# D1H register map
Vendor: Allwinner; File version: 1.0
Registers are 32-bit, read-write, reset 0x0 unless marked. A register's access mark holds for its fields unless they carry their own. Offsets are from the block's base; [hi:lo] are bit positions; {n}, {i} and the like mark numbered series.

## EMAC — Ethernet Medium Access Controller
Base 0x04500000
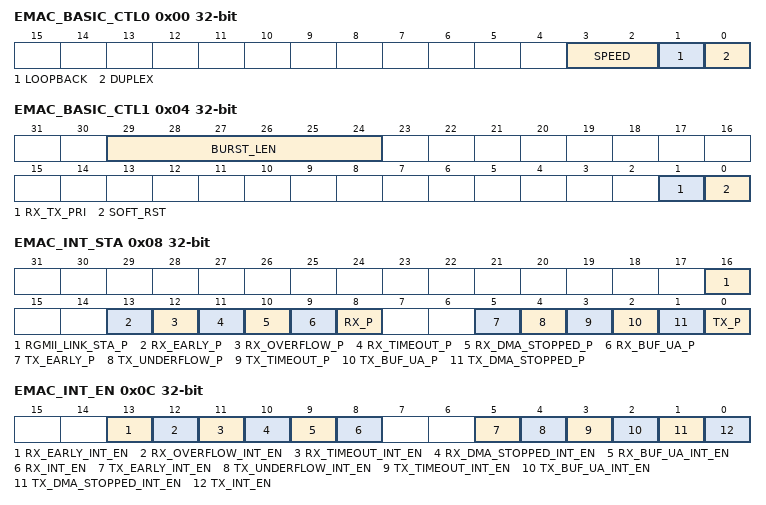
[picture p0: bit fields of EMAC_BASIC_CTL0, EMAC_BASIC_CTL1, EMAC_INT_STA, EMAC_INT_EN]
0x00 EMAC_BASIC_CTL0 — EMAC Basic Control Register0
  [3:2] SPEED — EMAC Working Speed
    0=S1000; 2=S10; 3=S100
  [1] LOOPBACK — EMAC Loopback Mode For Test
    0=Disable; 1=Enable
  [0] DUPLEX — EMAC Transfer Mode
    0=Half_Duplex; 1=Full_Duplex
0x04 EMAC_BASIC_CTL1 — EMAC Basic Control Register1
  [29:24] BURST_LEN — The burst length of RX and TX DMA transfer
  [1] RX_TX_PRI — RX TX DMA Priority
    0=Same; 1=RoT
  [0] SOFT_RST — Soft Reset all Registers and Logic
    0=no_valid; 1=reset
0x08 EMAC_INT_STA write-1-clears — EMAC Interrupt Status Register
  [16] RGMII_LINK_STA_P — RMII Link Status Changed Interrupt Pending
    0=No_Pending; 1=Pending
  [13] RX_EARLY_P — RX DMA Filled First Data Buffer of the Receive Frame Interrupt Pending
    0=no_pending; 1=pending
  [12] RX_OVERFLOW_P — RX FIFO Overflow Error Interrupt Pending
    0=no_pending; 1=pending
  [11] RX_TIMEOUT_P — RX Timeout Interrupt Pending
    0=no_pending; 1=pending
  [10] RX_DMA_STOPPED_P — When this bit asserted, the RX DMA FSM is stopped.
  [9] RX_BUF_UA_P — RX Buffer UA Interrupt Pending
    0=no_pending; 1=pending
  [8] RX_P — Frame RX Completed Interrupt Pending
    0=no_pending; 1=pending
  [5] TX_EARLY_P — Total interrupt pending which the frame is transmitted to FIFO
    0=no_pending; 1=pending
  [4] TX_UNDERFLOW_P — TX FIFO Underflow Interrupt Pending
    0=no_pending; 1=pending
  [3] TX_TIMEOUT_P — Transmitter Timeout Interrupt Pending
    0=no_pending; 1=pending
  [2] TX_BUF_UA_P — TX Buffer UA Interrupt Pending
    0=no_pending; 1=pending
  [1] TX_DMA_STOPPED_P — Transmission DMA Stopped Interrupt Pending
    0=no_pending; 1=pending
  [0] TX_P — Frame Transmission Interrupt Pending
    0=no_pending; 1=pending
0x0C EMAC_INT_EN — EMAC Interrupt Enable Register
  [all] fields
    0=Disable; 1=Enable
  [13] RX_EARLY_INT_EN — Early Receive Interrupt
  [12] RX_OVERFLOW_INT_EN — Receive Overflow Interrupt
  [11] RX_TIMEOUT_INT_EN — Receive Timeout Interrupt
  [10] RX_DMA_STOPPED_INT_EN — Receive DMA FSM Stopped Interrupt
  [9] RX_BUF_UA_INT_EN — Receive Buffer Unavailable Interrupt
  [8] RX_INT_EN — Receive Interrupt
  [5] TX_EARLY_INT_EN — Early Transmit Interrupt
  [4] TX_UNDERFLOW_INT_EN — Transmit Underflow Interrupt
  [3] TX_TIMEOUT_INT_EN — Transmit Timeout Interrupt
  [2] TX_BUF_UA_INT_EN — Transmit Buffer Available Interrupt
  [1] TX_DMA_STOPPED_INT_EN — Transmit DMA FSM Stopped Interrupt
  [0] TX_INT_EN — Transmit Interrupt
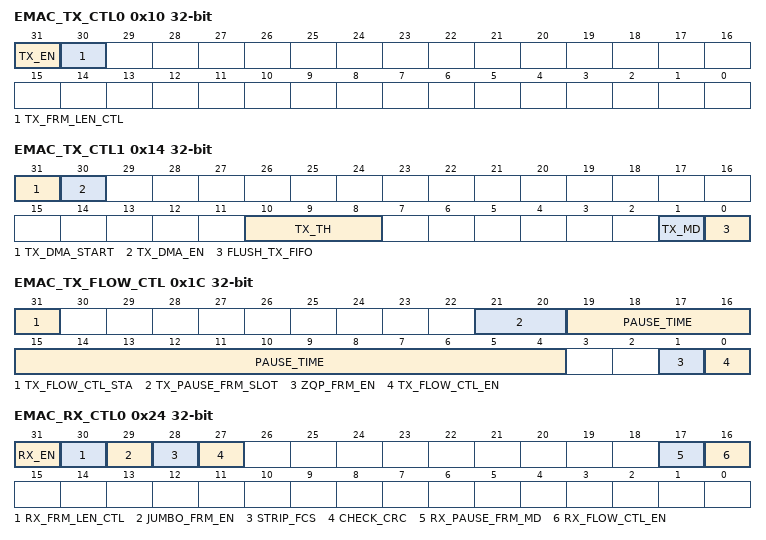
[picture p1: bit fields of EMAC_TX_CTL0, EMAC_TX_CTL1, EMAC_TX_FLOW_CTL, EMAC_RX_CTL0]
0x10 EMAC_TX_CTL0 — EMAC Transmit Control Register0
  [31] TX_EN — Enable Transmitter
    0=Disable; 1=Enable
  [30] TX_FRM_LEN_CTL — Frame Transmit Length Control
    0=B2048; 1=B16384
0x14 EMAC_TX_CTL1 — EMAC Transmit Control Register1
  [31] TX_DMA_START — Transmit DMA FSM Start
    0=no_valid; 1=start
  [30] TX_DMA_EN — Transmit DMA Enable
    0=stop; 1=start
  [10:8] TX_TH — Threshold value of TX DMA FIFO
    0=T64; 1=T128; 2=T192; 3=T256
  [1] TX_MD — Transmission Mode
    0=greater_than_th; 1=locate_full_frame
  [0] FLUSH_TX_FIFO — Flush the data in the TX FIFO
    0=enable; 1=disable
0x1C EMAC_TX_FLOW_CTL — EMAC Transmit Flow Control Register
  [31] TX_FLOW_CTL_STA
  [21:20] TX_PAUSE_FRM_SLOT
  [19:4] PAUSE_TIME
  [1] ZQP_FRM_EN
    0=disable; 1=enable
  [0] TX_FLOW_CTL_EN — TX Flow Control Enable
    0=disable; 1=enable
0x20 EMAC_TX_DMA_DESC_LIST — EMAC Transmit Descriptor List Address Register
0x24 EMAC_RX_CTL0 — EMAC Receive Control Register0
  [31] RX_EN — Enable Receiver
    0=disable; 1=enable
  [30] RX_FRM_LEN_CTL — Frame Receive Length Control
    0=B2048; 1=B16384
  [29] JUMBO_FRM_EN — Jumbo Frame Enable
    0=disable; 1=enable
  [28] STRIP_FCS
  [27] CHECK_CRC — Check CRC Enable
    0=disable; 1=check
  [17] RX_PAUSE_FRM_MD
    0=only_multicast; 1=also_unicast_mac0
  [16] RX_FLOW_CTL_EN
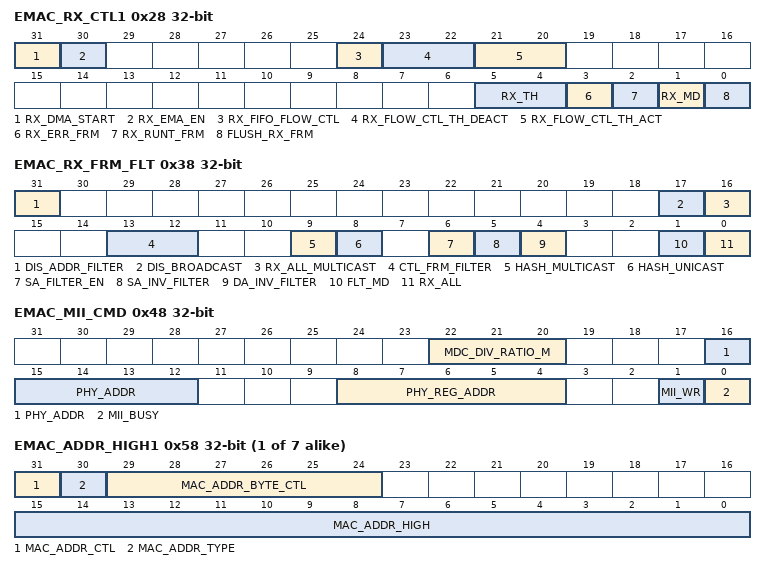
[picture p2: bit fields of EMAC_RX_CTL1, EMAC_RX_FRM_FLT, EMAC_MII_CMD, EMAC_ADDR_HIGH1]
0x28 EMAC_RX_CTL1 — EMAC Receive Control Register1
  [31] RX_DMA_START
  [30] RX_EMA_EN — Receive DMA Enable
    0=stop; 1=start
  [24] RX_FIFO_FLOW_CTL — Receive FIFO Flow Control Enable
    0=disable; 1=enable
  [23:22] RX_FLOW_CTL_TH_DEACT — Threshold for Deactivating Flow Control
    {v}=FM{v+1}K (v=0..3)
  [21:20] RX_FLOW_CTL_TH_ACT — Threshold for Activating Flow Control
    {v}=FM{v+1}K (v=0..3)
  [5:4] RX_TH — Threshold for RX DMA FIFO Start
    0=T64; 1=T32; 2=T96; 3=T128
  [3] RX_ERR_FRM
    0=drop; 1=forward
  [2] RX_RUNT_FRM
  [1] RX_MD — Receive Mode
    0=greater_than_th; 1=locate_full_frame
  [0] FLUSH_RX_FRM — Flush Receive Frames
    0=enable; 1=disable
0x34 EMAC_RX_DMA_DESC_LIST — EMAC Receive Descriptor List Address Register
0x38 EMAC_RX_FRM_FLT — EMAC Receive Frame Filter Register
  [31] DIS_ADDR_FILTER — Disable Address Filter
    0=Enable; 1=Disable
  [17] DIS_BROADCAST — Disable Receive Broadcast Frames
    0=Receive; 1=Drop
  [16] RX_ALL_MULTICAST — Receive All Multicast Frames Filter
    0=Filter; 1=Receive_all
  [13:12] CTL_FRM_FILTER — Receive Control Frames Filter
    0b0x=Drop_all; 2=Receive_all; 3=Receive_all_when_filter
  [9] HASH_MULTICAST — Filter Multicast Frames Set
    0=DA_field; 1=hash_table
  [8] HASH_UNICAST — Filter Unicast Frames Set
    0=DA_field; 1=hash_table
  [6] SA_FILTER_EN — Receive SA Filter Enable
    0=receive_update; 1=update_drop_unmatched
  [5] SA_INV_FILTER — Receive SA Invert Filter Set
    0=matched; 1=unmatched
  [4] DA_INV_FILTER
    0=normal; 1=inverse_cmp_da
  [1] FLT_MD
    0=passed_when_matched; 1=receive_when_passed
  [0] RX_ALL — Receive All Frame
    0=receive_when_passed; 1=receive_all_update
0x40 EMAC_RX_HASH0 — EMAC Hash Table Register0
0x44 EMAC_RX_HASH1 — EMAC Hash Table Register1
0x48 EMAC_MII_CMD — EMAC Management Interface Command Register
  [22:20] MDC_DIV_RATIO_M — MDC Clock DIvider Ratio
    0=R16; 1=R32; 2=R64; 3=R128
  [16:12] PHY_ADDR — PHY Address
  [8:4] PHY_REG_ADDR — PHY Register Address
  [1] MII_WR — MII Write and Read
    0=R; 1=W
  [0] MII_BUSY — MII Status
0x4C EMAC_MII_DATA — EMAC Management Interface Data Register
  [15:0] MII_DATA
0x50 EMAC_ADDR_HIGH0 — EMAC MAC Address High Register
  [15:0] MAC_ADDR_HIGH0
{0x54+8i} EMAC_ADDR_LOW{i} (i=0..7) — EMAC MAC Address Low Register
{0x50+8i} EMAC_ADDR_HIGH{i} (i=1..7) — EMAC MAC Address High Register
  [31] MAC_ADDR_CTL — MAC Address Valid
    0=invalid; 1=valid
  [30] MAC_ADDR_TYPE — MAC Address Type
    0=dst; 1=src
  [29:24] MAC_ADDR_BYTE_CTL — MAC Address Byte Control Mask
  [15:0] MAC_ADDR_HIGH
0xB0 EMAC_TX_DMA_STA ro — EMAC Transmit DMA Status Register
  [2:0] TX_DMA_STA — The State of Transmit DMA FSM
    0=stop; 1=run_fetch_desc; 2=run_wait_sta; 3=run_trans_data; 6=suspend; 7=run_close_desc
0xB4 EMAC_TX_CUR_DESC ro — EMAC Current Transmit Descriptor Register
0xB8 EMAC_TX_CUR_BUF ro — EMAC Current Transmit Buffer Address Register
0xC0 EMAC_RX_DMA_STA ro — EMAC Receive DMA Status Register
  [2:0] RX_DMA_STA — The State of RX DMA FSM
    0=stop; 1=run_fetch_desc; 3=run_wait_frm; 4=suspend; 5=run_close_desc; 7=run_trans_data
0xC4 EMAC_RX_CUR_DESC ro — EMAC Current Receive Descriptor Register
0xC8 EMAC_RX_CUR_BUF ro — EMAC Current Receive Buffer Address Register
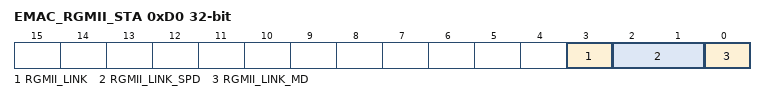
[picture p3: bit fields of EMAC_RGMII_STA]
0xD0 EMAC_RGMII_STA — EMAC RGMII Status Register
  [3] RGMII_LINK — The link status of the RGMII interface
    0=down; 1=up
  [2:1] RGMII_LINK_SPD — The link speed of the RGMII interface
    0=S2_5; 1=S25; 2=S125
  [0] RGMII_LINK_MD — The link mode of the RGMII interface
    0=half_duplex; 1=full_duplex
